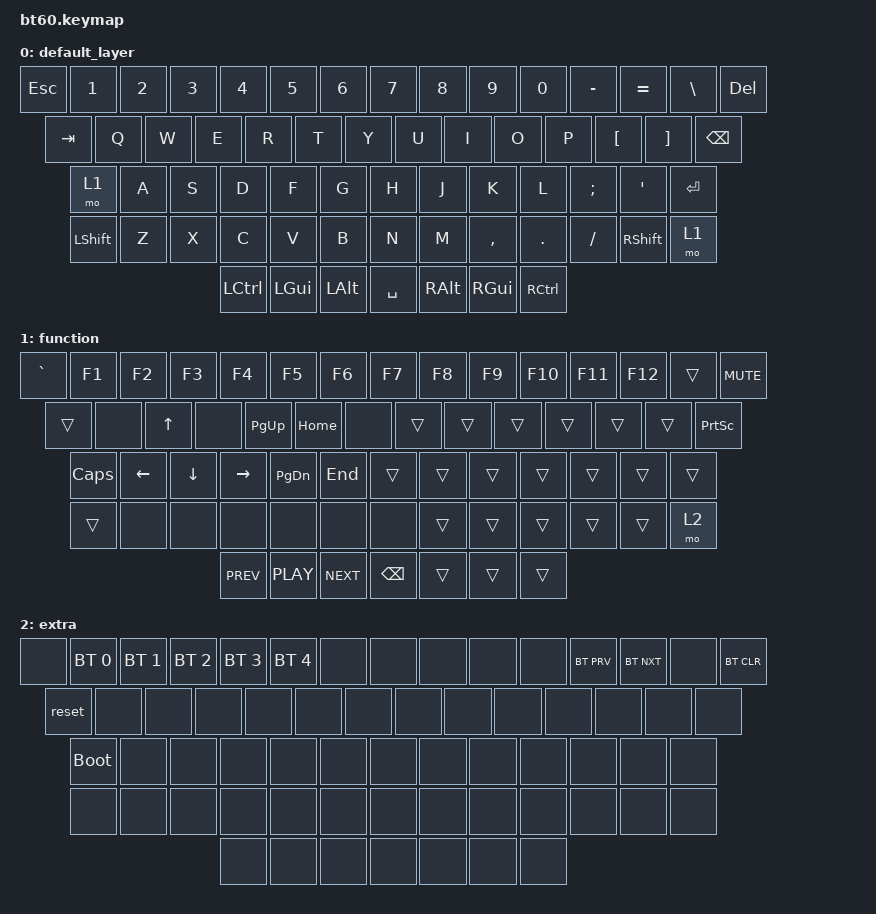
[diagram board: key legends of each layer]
#include <behaviors.dtsi>
#include <dt-bindings/zmk/keys.h>
#include <dt-bindings/zmk/bt.h>

/ {
	keymap {
		compatible = "zmk,keymap";

		default_layer {
				// ------------------------------------------------------------------------------------------
				// | ESC |  1  |  2  |  3  |  4  |  5  |  6  |  7  |  8  |  9  |  0  |  -  |  =  |BSLH |DEL |
				// | TAB  |  Q  |  W  |  E  |  R  |  T  |  Y  |  U  |  I  |  O  |  P  |  [  |  ]  |   "|"   |
				// |  FN  |  A  |  S  |  D  |  F  |  G  |  H  |  J  |  K  |  L  |  ;  |  '  |     ENTER     |
				// |  SHIFT    |  Z  |  X  |  C  |  V  |  B  |  N  |  M  |  ,  |  .  | /   |   SHIFT   | FN |
				// |  CTRL |  WIN  |  ALT  |                   SPACE                 |  ALT  |  WIN  | CTRL |
				// ------------------------------------------------------------------------------------------
			bindings = <
				&kp ESC &kp N1 &kp N2 &kp N3 &kp N4 &kp N5 &kp N6 &kp N7 &kp  N8   &kp  N9 &kp  N0  &kp MINUS &kp EQUAL &kp BSLH &kp DEL
				&kp TAB  &kp Q  &kp W  &kp E  &kp R  &kp T  &kp Y  &kp U  &kp  I    &kp  O  &kp  P   &kp LBKT &kp RBKT  &kp BSPC
				&mo 1  &kp A  &kp S  &kp D  &kp F  &kp G  &kp H  &kp J  &kp  K    &kp  L  &kp SEMI &kp SQT           &kp RET
				&kp LSHFT  &kp Z  &kp X  &kp C  &kp V  &kp B  &kp N  &kp M  &kp COMMA &kp DOT &kp FSLH    &kp RSHFT    &mo 1
				&kp LCTRL &kp LGUI &kp LALT            &kp SPACE                        	     &kp RALT &kp RGUI &kp RCTRL
			>;
			sensor-bindings = <&inc_dec_kp C_NEXT C_PREV>;
		};
		function {
			bindings = <
				&kp GRAVE &kp F1 &kp F2 &kp F3 &kp F4 &kp F5 &kp F6 &kp F7 &kp F8 &kp F9 &kp F10  &kp F11 &kp F12 &trans &kp C_MUTE
				&trans &none &kp UP &none &kp PG_UP &kp HOME &none &trans &trans &trans &trans &trans &trans &kp PSCRN
				&kp CLCK  &kp LEFT &kp DOWN &kp RIGHT &kp PG_DN &kp END &trans &trans &trans &trans &trans  &trans &trans
				&trans &none &none &none &none &none &none &trans &trans &trans &trans &trans  &mo 2
				&kp C_PREV &kp C_PLAY  &kp C_NEXT                     &kp BSPC                            	     &trans &trans &trans
			>;
			sensor-bindings = <&inc_dec_kp C_VOL_UP C_VOL_DN>;
		};
		extra {
			bindings = <
				&none &bt BT_SEL 0 &bt BT_SEL 1 &bt BT_SEL 2 &bt BT_SEL 3 &bt BT_SEL 4 &none &none &none &none &none &bt BT_PRV &bt BT_NXT &none &bt BT_CLR
				&reset &none &none &none &none &none &none &none &none &none &none &none &none &none
				&bootloader  &none &none &none &none &none &none &none &none &none &none  &none &none
				&none &none&none &none &none &none &none &none &none &none &none &none &none
				&none &none &none                     &none                            	      &none &none &none
			>;
			sensor-bindings = <&inc_dec_kp C_VOL_UP C_VOL_DN>;
		};
	};
};
